# PIC16F1937 register map
File version: 1.0
PIC16F1937 special function registers
Registers are 8-bit, read-write, reset 0x0 unless marked. A register's access mark holds for its fields unless they carry their own. Offsets are from the block's base; lines under a group give offsets from that group; [hi:lo] are bit positions; {n}, {i} and the like mark numbered series; 'fields as' and 'values as' point back to an identical list; <NAME> marks a mode.

## Memory map
0x00800000 CPU size 0xFF0 — Core registers
0x0080000C PORTA size 0x181
0x0080000D PORTB size 0x38A
0x0080000E PORTC size 0x101
0x0080000F PORTD size 0x181
0x00800010 PORTE size 0x201
0x00800011 INTERRUPTS size 0x83 — Interrupt flags and enables
0x00800015 TIMER0 size 0x1
0x00800016 TIMER1 size 0x4
0x0080001A TIMER2 size 0x3
0x0080001E CAPSENSE size 0x2 — Capacitive sensing
0x00800095 SYSTEM size 0x89 — Reset, watchdog and pin options
0x00800098 OSCILLATOR size 0x3
0x0080009B ADC size 0x4 — Analog-to-digital converter
0x00800111 COMPARATORS size 0x5
0x00800117 REFERENCES size 0x5 — Voltage reference, DAC and SR latch
0x00800191 NVM size 0x6 — Flash and EEPROM access
0x00800199 EUSART size 0x7
0x00800211 MSSP size 0x7 — Synchronous serial port
0x00800291 CCP size 0x8E — Capture, compare and PWM
0x00800415 TIMER4 size 0x3
0x0080041C TIMER6 size 0x3
0x00800791 LCD size 0x1B — LCD driver

## CPU — Core registers
Base 0x00800000
0x00 INDF0 reset not defined — INDF0, data address 0x000
0x01 INDF1 reset not defined — INDF1, data address 0x001
0x02 PCL — PCL, data address 0x002
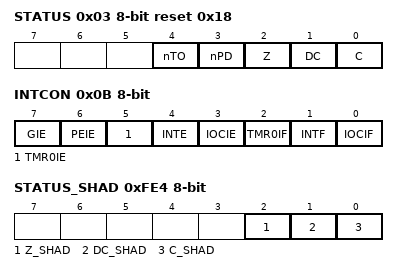
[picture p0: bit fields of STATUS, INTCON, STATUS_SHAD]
0x03 STATUS reset 0x18 — STATUS, data address 0x003
  [4] nTO, [3] nPD, [2] Z, [1] DC, [0] C
0x04 FSR0L — FSR0L, data address 0x004
0x05 FSR0H — FSR0H, data address 0x005
0x06 FSR1L — FSR1L, data address 0x006
0x07 FSR1H — FSR1H, data address 0x007
0x08 BSR — BSR, data address 0x008
  [4:0] BSR
0x09 WREG — WREG, data address 0x009
  [7:0] WREG0
0x0A PCLATH — PCLATH, data address 0x00a
  [6:0] PCLATH
0x0B INTCON — INTCON, data address 0x00b
  [7] GIE, [6] PEIE, [5] TMR0IE, [4] INTE, [3] IOCIE, [2] TMR0IF, [1] INTF, [0] IOCIF
0xFE4 STATUS_SHAD reset not defined — STATUS_SHAD, data address 0xfe4
  [2] Z_SHAD, [1] DC_SHAD, [0] C_SHAD
0xFE5 WREG_SHAD reset not defined — WREG_SHAD, data address 0xfe5
0xFE6 BSR_SHAD reset not defined — BSR_SHAD, data address 0xfe6
  [4:0] BSR_SHAD
0xFE7 PCLATH_SHAD reset not defined — PCLATH_SHAD, data address 0xfe7
  [6:0] PCLATH_SHAD
0xFE8 FSR0L_SHAD reset not defined — FSR0L_SHAD, data address 0xfe8
0xFE9 FSR0H_SHAD reset not defined — FSR0H_SHAD, data address 0xfe9
0xFEA FSR1L_SHAD reset not defined — FSR1L_SHAD, data address 0xfea
0xFEB FSR1H_SHAD reset not defined — FSR1H_SHAD, data address 0xfeb
0xFED STKPTR reset 0x1F — STKPTR, data address 0xfed
  [4:0] STKPTR
0xFEE TOSL reset not defined — TOSL, data address 0xfee
0xFEF TOSH reset not defined — TOSH, data address 0xfef
  [6:0] TOSH

## ADC — Analog-to-digital converter
Base 0x0080009B
0x00 ADRESL reset not defined — ADRESL, data address 0x09b
0x01 ADRESH reset not defined — ADRESH, data address 0x09c
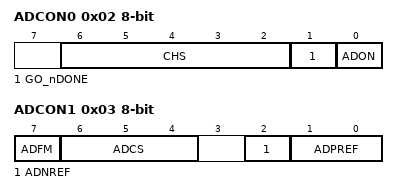
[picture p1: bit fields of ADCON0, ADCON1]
0x02 ADCON0 — ADCON0, data address 0x09d
  [6:2] CHS, [1] GO_nDONE, [0] ADON
0x03 ADCON1 — ADCON1, data address 0x09e
  [7] ADFM, [6:4] ADCS, [2] ADNREF, [1:0] ADPREF

## CAPSENSE — Capacitive sensing
Base 0x0080001E
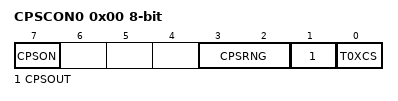
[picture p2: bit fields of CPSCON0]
0x00 CPSCON0 — CPSCON0, data address 0x01e
  [7] CPSON, [3:2] CPSRNG, [1] CPSOUT, [0] T0XCS
0x01 CPSCON1 — CPSCON1, data address 0x01f
  [3:0] CPSCH

## CCP — Capture, compare and PWM
Base 0x00800291
0x00 CCPR1L reset not defined — CCPR1L, data address 0x291
0x01 CCPR1H reset not defined — CCPR1H, data address 0x292
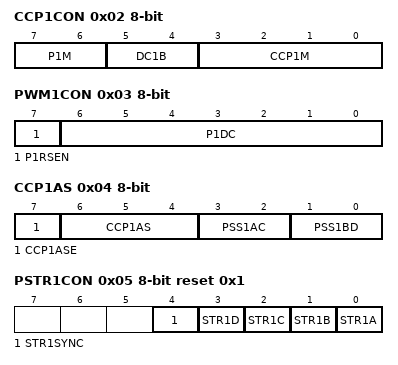
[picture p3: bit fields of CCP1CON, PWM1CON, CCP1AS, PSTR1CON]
0x02 CCP1CON — CCP1CON, data address 0x293
  [7:6] P1M, [5:4] DC1B, [3:0] CCP1M
0x03 PWM1CON — PWM1CON, data address 0x294
  [7] P1RSEN, [6:0] P1DC
0x04 CCP1AS — CCP1AS, data address 0x295
  [7] CCP1ASE, [6:4] CCP1AS, [3:2] PSS1AC, [1:0] PSS1BD
0x05 PSTR1CON reset 0x1 — PSTR1CON, data address 0x296
  [4] STR1SYNC, [3] STR1D, [2] STR1C, [1] STR1B, [0] STR1A
0x07 CCPR2L reset not defined — CCPR2L, data address 0x298
0x08 CCPR2H reset not defined — CCPR2H, data address 0x299
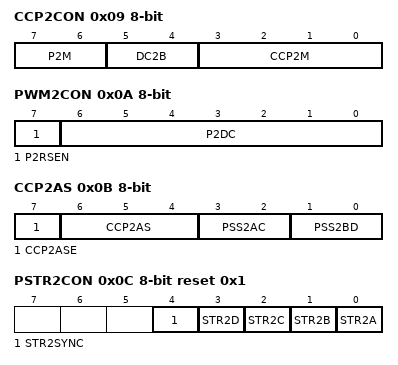
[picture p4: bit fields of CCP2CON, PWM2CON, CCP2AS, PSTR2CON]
0x09 CCP2CON — CCP2CON, data address 0x29a
  [7:6] P2M, [5:4] DC2B, [3:0] CCP2M
0x0A PWM2CON — PWM2CON, data address 0x29b
  [7] P2RSEN, [6:0] P2DC
0x0B CCP2AS — CCP2AS, data address 0x29c
  [7] CCP2ASE, [6:4] CCP2AS, [3:2] PSS2AC, [1:0] PSS2BD
0x0C PSTR2CON reset 0x1 — PSTR2CON, data address 0x29d
  [4] STR2SYNC, [3] STR2D, [2] STR2C, [1] STR2B, [0] STR2A
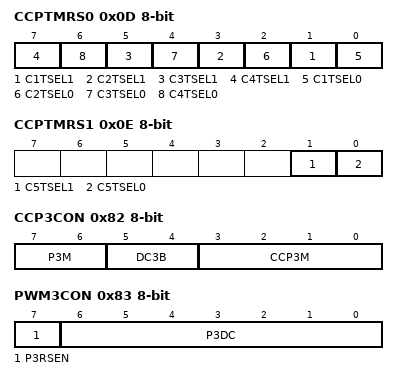
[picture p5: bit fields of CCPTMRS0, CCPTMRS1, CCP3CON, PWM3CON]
0x0D CCPTMRS0 — CCPTMRS0, data address 0x29e
  [2n-1] C{n}TSEL1 (n=1..4), [2n-2] C{n}TSEL0 (n=1..4)
0x0E CCPTMRS1 — CCPTMRS1, data address 0x29f
  [1] C5TSEL1, [0] C5TSEL0
0x80 CCPR3L reset not defined — CCPR3L, data address 0x311
0x81 CCPR3H reset not defined — CCPR3H, data address 0x312
0x82 CCP3CON — CCP3CON, data address 0x313
  [7:6] P3M, [5:4] DC3B, [3:0] CCP3M
0x83 PWM3CON — PWM3CON, data address 0x314
  [7] P3RSEN, [6:0] P3DC
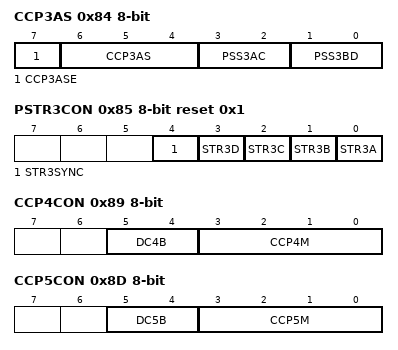
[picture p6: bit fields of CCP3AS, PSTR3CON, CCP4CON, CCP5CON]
0x84 CCP3AS — CCP3AS, data address 0x315
  [7] CCP3ASE, [6:4] CCP3AS, [3:2] PSS3AC, [1:0] PSS3BD
0x85 PSTR3CON reset 0x1 — PSTR3CON, data address 0x316
  [4] STR3SYNC, [3] STR3D, [2] STR3C, [1] STR3B, [0] STR3A
0x87 CCPR4L reset not defined — CCPR4L, data address 0x318
0x88 CCPR4H reset not defined — CCPR4H, data address 0x319
0x89 CCP4CON — CCP4CON, data address 0x31a
  [5:4] DC4B, [3:0] CCP4M
0x8B CCPR5L reset not defined — CCPR5L, data address 0x31c
0x8C CCPR5H reset not defined — CCPR5H, data address 0x31d
0x8D CCP5CON — CCP5CON, data address 0x31e
  [5:4] DC5B, [3:0] CCP5M
